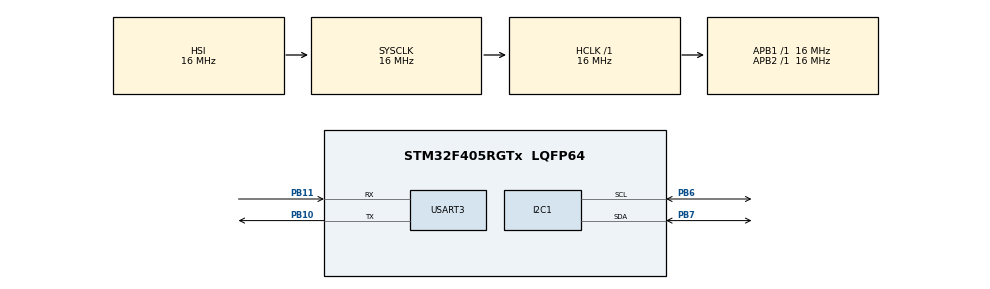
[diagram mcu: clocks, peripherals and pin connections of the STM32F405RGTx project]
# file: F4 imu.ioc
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Dma.Request0=USART3_RX
Dma.Request1=USART3_TX
Dma.USART3_RX.0.Direction=DMA_PERIPH_TO_MEMORY
Dma.USART3_RX.0.FIFOMode=DMA_FIFOMODE_DISABLE
Dma.USART3_RX.0.Instance=DMA1_Stream1
Dma.USART3_RX.0.MemDataAlignment=DMA_MDATAALIGN_BYTE
Dma.USART3_RX.0.MemInc=DMA_MINC_ENABLE
Dma.USART3_RX.0.Mode=DMA_NORMAL
Dma.USART3_RX.0.PeriphDataAlignment=DMA_PDATAALIGN_BYTE
Dma.USART3_RX.0.PeriphInc=DMA_PINC_DISABLE
Dma.USART3_RX.0.Priority=DMA_PRIORITY_LOW
Dma.USART3_TX.1.Direction=DMA_MEMORY_TO_PERIPH
Dma.USART3_TX.1.FIFOMode=DMA_FIFOMODE_DISABLE
Dma.USART3_TX.1.Instance=DMA1_Stream3
Dma.USART3_TX.1.MemDataAlignment=DMA_MDATAALIGN_BYTE
Dma.USART3_TX.1.MemInc=DMA_MINC_ENABLE
Dma.USART3_TX.1.Mode=DMA_NORMAL
Dma.USART3_TX.1.PeriphDataAlignment=DMA_PDATAALIGN_BYTE
Dma.USART3_TX.1.PeriphInc=DMA_PINC_DISABLE
Dma.USART3_TX.1.Priority=DMA_PRIORITY_LOW
FREERTOS.Tasks01=defaultTask,0,128,StartDefaultTask,Default,NULL,Dynamic,NULL,NULL;read_imuTask,-3,128,read_imuStartTask,Default,NULL,Dynamic,NULL,NULL
Mcu.Family=STM32F4
Mcu.Name=STM32F405RGTx
Mcu.Package=LQFP64
NVIC.DMA1_Stream1_IRQn=true\:5\:0\:false\:false\:true\:true\:false\:true\:true
NVIC.DMA1_Stream3_IRQn=true\:5\:0\:false\:false\:true\:true\:false\:true\:true
NVIC.PriorityGroup=NVIC_PRIORITYGROUP_4
NVIC.TIM1_UP_TIM10_IRQn=true\:15\:0\:false\:false\:true\:false\:false\:true\:true
NVIC.TimeBase=TIM1_UP_TIM10_IRQn
NVIC.TimeBaseIP=TIM1
NVIC.USART3_IRQn=true\:5\:0\:false\:false\:true\:true\:true\:true\:true
PA13.Mode=Serial_Wire
PA13.Signal=SYS_JTMS-SWDIO
PA14.Mode=Serial_Wire
PA14.Signal=SYS_JTCK-SWCLK
PB10.Mode=Asynchronous
PB10.Signal=USART3_TX
PB11.Mode=Asynchronous
PB11.Signal=USART3_RX
PB6.Mode=I2C
PB6.Signal=I2C1_SCL
PB7.Mode=I2C
PB7.Signal=I2C1_SDA
PC14-OSC32_IN.Mode=LSE-External-Oscillator
PC14-OSC32_IN.Signal=RCC_OSC32_IN
PC15-OSC32_OUT.Mode=LSE-External-Oscillator
PC15-OSC32_OUT.Signal=RCC_OSC32_OUT
PH0-OSC_IN.Mode=HSE-External-Oscillator
PH0-OSC_IN.Signal=RCC_OSC_IN
PH1-OSC_OUT.Mode=HSE-External-Oscillator
PH1-OSC_OUT.Signal=RCC_OSC_OUT
ProjectManager.HeapSize=0x200
ProjectManager.StackSize=0x400
ProjectManager.TargetToolchain=MDK-ARM V5.32
RCC.AHBFreq_Value=16000000
RCC.APB1Freq_Value=16000000
RCC.APB2Freq_Value=16000000
RCC.CortexFreq_Value=16000000
RCC.HSE_VALUE=25000000
RCC.HSI_VALUE=16000000
RCC.SYSCLKFreq_VALUE=16000000
RCC.VCOOutputFreq_Value=192000000
USART3.VirtualMode=VM_ASYNC
VP_FREERTOS_VS_CMSIS_V1.Mode=CMSIS_V1
VP_SYS_VS_tim1.Mode=TIM1
board=custom

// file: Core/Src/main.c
/* USER CODE BEGIN Header */
/**
  ******************************************************************************
  * @file           : main.c
  * @brief          : Main program body
  ******************************************************************************
  * @attention
  *
  * Copyright (c) 2024 STMicroelectronics.
  * All rights reserved.
  *
  * This software is licensed under terms that can be found in the LICENSE file
  * in the root directory of this software component.
  * If no LICENSE file comes with this software, it is provided AS-IS.
  *
  ******************************************************************************
  */
/* USER CODE END Header */
#include "main.h"
#include "cmsis_os.h"
#include "dma.h"
#include "i2c.h"
#include "usart.h"
#include "gpio.h"
#include "stdio.h"
/* USER CODE BEGIN Includes */
#include "MPU6050.h"
/* USER CODE END Includes */

void SystemClock_Config(void);
void MX_FREERTOS_Init(void);

int main(void)
{

  /* MCU Configuration--------------------------------------------------------*/

  /* Reset of all peripherals, Initializes the Flash interface and the Systick. */
  HAL_Init();

  /* Configure the system clock */
  SystemClock_Config();

  /* Initialize all configured peripherals */
  MX_GPIO_Init();
  MX_DMA_Init();
  MX_I2C1_Init();
  MX_USART3_UART_Init();
  /* USER CODE BEGIN 2 */
	 int ret=0;
	do{
	 ret=MPU6050_DMP_init();
		printf("ret");
	}while(ret);
  /* USER CODE END 2 */

  /* Call init function for freertos objects (in freertos.c) */
  MX_FREERTOS_Init();

  /* Start scheduler */
  osKernelStart();
  /* We should never get here as control is now taken by the scheduler */
  /* Infinite loop */
  while (1)
  {

  }
}

void SystemClock_Config(void)
{
  RCC_OscInitTypeDef RCC_OscInitStruct = {0};
  RCC_ClkInitTypeDef RCC_ClkInitStruct = {0};

  /** Configure the main internal regulator output voltage
  */
  __HAL_RCC_PWR_CLK_ENABLE();
  __HAL_PWR_VOLTAGESCALING_CONFIG(PWR_REGULATOR_VOLTAGE_SCALE1);

  /** Initializes the RCC Oscillators according to the specified parameters
  * in the RCC_OscInitTypeDef structure.
  */
  RCC_OscInitStruct.OscillatorType = RCC_OSCILLATORTYPE_HSI;
  RCC_OscInitStruct.HSIState = RCC_HSI_ON;
  RCC_OscInitStruct.HSICalibrationValue = RCC_HSICALIBRATION_DEFAULT;
  RCC_OscInitStruct.PLL.PLLState = RCC_PLL_NONE;
  if (HAL_RCC_OscConfig(&RCC_OscInitStruct) != HAL_OK)
  {
    Error_Handler();
  }

  /** Initializes the CPU, AHB and APB buses clocks
  */
  RCC_ClkInitStruct.ClockType = RCC_CLOCKTYPE_HCLK|RCC_CLOCKTYPE_SYSCLK
                              |RCC_CLOCKTYPE_PCLK1|RCC_CLOCKTYPE_PCLK2;
  RCC_ClkInitStruct.SYSCLKSource = RCC_SYSCLKSOURCE_HSI;
  RCC_ClkInitStruct.AHBCLKDivider = RCC_SYSCLK_DIV1;
  RCC_ClkInitStruct.APB1CLKDivider = RCC_HCLK_DIV1;
  RCC_ClkInitStruct.APB2CLKDivider = RCC_HCLK_DIV1;

  if (HAL_RCC_ClockConfig(&RCC_ClkInitStruct, FLASH_LATENCY_0) != HAL_OK)
  {
    Error_Handler();
  }
}

void HAL_TIM_PeriodElapsedCallback(TIM_HandleTypeDef *htim)
{
  if (htim->Instance == TIM1) {
    HAL_IncTick();
  }
}

void Error_Handler(void)
{
  __disable_irq();
  while (1)
  {
  }
}

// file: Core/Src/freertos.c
/* USER CODE BEGIN Header */
/**
  ******************************************************************************
  * File Name          : freertos.c
  * Description        : Code for freertos applications
  ******************************************************************************
  * @attention
  *
  * Copyright (c) 2024 STMicroelectronics.
  * All rights reserved.
  *
  * This software is licensed under terms that can be found in the LICENSE file
  * in the root directory of this software component.
  * If no LICENSE file comes with this software, it is provided AS-IS.
  *
  ******************************************************************************
  */
/* USER CODE END Header */

#include "FreeRTOS.h"
#include "task.h"
#include "main.h"
#include "cmsis_os.h"

/* USER CODE BEGIN Includes */
#include "MPU6050.h"
#include "usart.h"
#include "stdio.h"
#include "string.h"
/* USER CODE END Includes */

/* USER CODE BEGIN PTD */
float pitch,yaw,roll;
/* USER CODE END PTD */

osThreadId defaultTaskHandle;
osThreadId read_imuTaskHandle;

void StartDefaultTask(void const * argument);
void read_imuStartTask(void const * argument);

void MX_FREERTOS_Init(void); /* (MISRA C 2004 rule 8.1) */

/* GetIdleTaskMemory prototype (linked to static allocation support) */
void vApplicationGetIdleTaskMemory( StaticTask_t **ppxIdleTaskTCBBuffer, StackType_t **ppxIdleTaskStackBuffer, uint32_t *pulIdleTaskStackSize );

/* USER CODE BEGIN GET_IDLE_TASK_MEMORY */
static StaticTask_t xIdleTaskTCBBuffer;
static StackType_t xIdleStack[configMINIMAL_STACK_SIZE];

void vApplicationGetIdleTaskMemory( StaticTask_t **ppxIdleTaskTCBBuffer, StackType_t **ppxIdleTaskStackBuffer, uint32_t *pulIdleTaskStackSize )
{
  *ppxIdleTaskTCBBuffer = &xIdleTaskTCBBuffer;
  *ppxIdleTaskStackBuffer = &xIdleStack[0];
  *pulIdleTaskStackSize = configMINIMAL_STACK_SIZE;
  /* place for user code */
}
/* USER CODE END GET_IDLE_TASK_MEMORY */

void MX_FREERTOS_Init(void) {

  /* Create the thread(s) */
  /* definition and creation of defaultTask */
  osThreadDef(defaultTask, StartDefaultTask, osPriorityNormal, 0, 128);
  defaultTaskHandle = osThreadCreate(osThread(defaultTask), NULL);

  /* definition and creation of read_imuTask */
  osThreadDef(read_imuTask, read_imuStartTask, osPriorityIdle, 0, 128);
  read_imuTaskHandle = osThreadCreate(osThread(read_imuTask), NULL);

}

void StartDefaultTask(void const * argument)
{
  /* USER CODE BEGIN StartDefaultTask */
  /* Infinite loop */

	// printf("ret=%d\n",ret);

  for(;;)
  {
		MPU6050_DMP_Get_Date(&pitch,&roll,&yaw);
    osDelay(1);
  }
  /* USER CODE END StartDefaultTask */
}

void read_imuStartTask(void const * argument)
{
  /* USER CODE BEGIN read_imuStartTask */
  /* Infinite loop */
  for(;;)
  {
	 printf("pitch=%f yaw=%f roll=%f\n",pitch,yaw,roll);
    osDelay(1);
  }
  /* USER CODE END read_imuStartTask */
}
